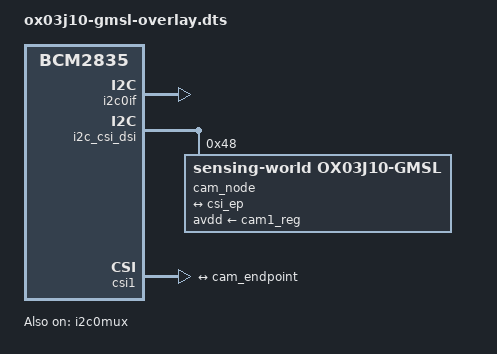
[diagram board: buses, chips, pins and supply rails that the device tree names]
// SPDX-License-Identifier: GPL-2.0-only
// Definitions for OX03J10 GMSL2 camera module on VC I2C bus
/dts-v1/;
/plugin/;

/ {
	compatible = "brcm,bcm2835";

	fragment@0 {
		target = <&i2c0if>;
		__overlay__ {
			status = "okay";
		};
	};

	clk_frag: fragment@1 {
		target = <&cam1_clk>;
		cam_clk: __overlay__ {
			status = "okay";
			clock-frequency = <24000000>;
		};
	};

	fragment@2 {
		target = <&i2c0mux>;
		__overlay__ {
			status = "okay";
		};
	};

	reg_frag: fragment@3 {
		target = <&cam1_reg>;
		cam_reg: __overlay__ {
			startup-delay-us = <100000>;
		};
	};

	i2c_frag: fragment@100 {
		target = <&i2c_csi_dsi>;
		__overlay__ {
			#address-cells = <1>;
			#size-cells = <0>;
			status = "okay";

			cam_node: camera@48 {
				compatible = "sensing-world,ox03j10-gmsl";
				reg = <0x48>;
				max9296-addr = <0x48>;
				max96717-addr = <0x40>;
				sensor-addr = <0x36>;
				clocks = <&cam1_clk>;
				clock-names = "xvclk";
				avdd-supply = <&cam1_reg>;
				status = "okay";

				port {
					cam_endpoint: endpoint {
						clock-lanes = <0>;
						data-lanes = <1 2 3 4>;
						link-frequencies =
							/bits/ 64 <1200000000>;
						remote-endpoint = <&csi_ep>;
					};
				};
			};
		};
	};

	csi_frag: fragment@101 {
		target = <&csi1>;
		csi: __overlay__ {
			status = "okay";
			brcm,media-controller;

			port {
				csi_ep: endpoint {
					remote-endpoint = <&cam_endpoint>;
					clock-lanes = <0>;
					data-lanes = <1 2 3 4>;
				};
			};
		};
	};

	fragment@4 {
		target = <&cam_endpoint>;
		__dormant__ {
			data-lanes = <1 2>;
		};
	};

	fragment@5 {
		target = <&csi_ep>;
		__dormant__ {
			data-lanes = <1 2>;
		};
	};

	__overrides__ {
		2lane = <0>, "+4+5";
		max9296-addr = <&cam_node>, "max9296-addr:0";
		max96717-addr = <&cam_node>, "max96717-addr:0";
		sensor-addr = <&cam_node>, "sensor-addr:0";
		media-controller = <&csi>, "brcm,media-controller?";
		cam0 = <&i2c_frag>, "target:0=", <&i2c_csi_dsi0>,
		       <&csi_frag>, "target:0=", <&csi0>,
		       <&reg_frag>, "target:0=", <&cam0_reg>,
		       <&clk_frag>, "target:0=", <&cam0_clk>,
		       <&cam_node>, "clocks:0=", <&cam0_clk>,
		       <&cam_node>, "avdd-supply:0=", <&cam0_reg>;
	};
};
